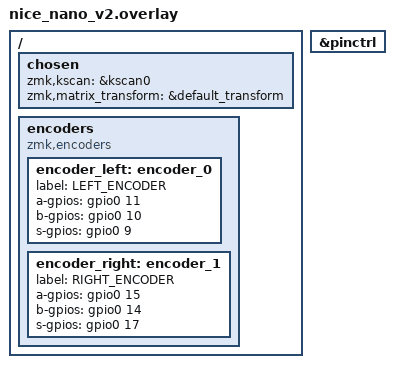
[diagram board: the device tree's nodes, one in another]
// #include <dt-bindings/led/led.h> (Removido, não é mais necessário sem o LED)
#include <dt-bindings/zmk/matrix_transform.h> // Garantir que está incluído se não estiver no principal

&pinctrl {
    // A seção SPI3 e o RGB foram removidos
};

/ {
    // A seção 'chosen' do RGB foi removida

    // --- ENCODERS: Definição dos Pinos e Configuração ---
    // (Esta seção DEVE estar no seu arquivo overlay ou em um include)

    chosen {
        zmk,kscan = &kscan0;
        zmk,matrix_transform = &default_transform;
    };

    encoders {
        compatible = "zmk,encoders";

        // Encoder Esquerdo (Master/Left)
        encoder_left: encoder_0 {
            status = "okay";
            label = "LEFT_ENCODER";
            // Pinos A e B para a rotação
            a-gpios = <&gpio0 11 (GPIO_PULL_UP | GPIO_FLAGS_ENCODER_RA)>;
            b-gpios = <&gpio0 10 (GPIO_PULL_UP | GPIO_FLAGS_ENCODER_RB)>;
            // Pino do BOTÃO/SWITCH
            s-gpios = <&gpio0 9 (GPIO_PULL_UP)>;
        };

        // Encoder Direito (Slave/Right)
        encoder_right: encoder_1 {
            status = "okay";
            label = "RIGHT_ENCODER";
            // Pinos A e B para a rotação
            a-gpios = <&gpio0 15 (GPIO_PULL_UP | GPIO_FLAGS_ENCODER_RA)>;
            b-gpios = <&gpio0 14 (GPIO_PULL_UP | GPIO_FLAGS_ENCODER_RB)>;
            s-gpios = <&gpio0 17 (GPIO_PULL_UP)>; 
        };
    };
};
// vim: filetype=dts fdm=marker:
